AUTOSAR XML (schema 4-2-1)
package /RootP_ASWC_M418
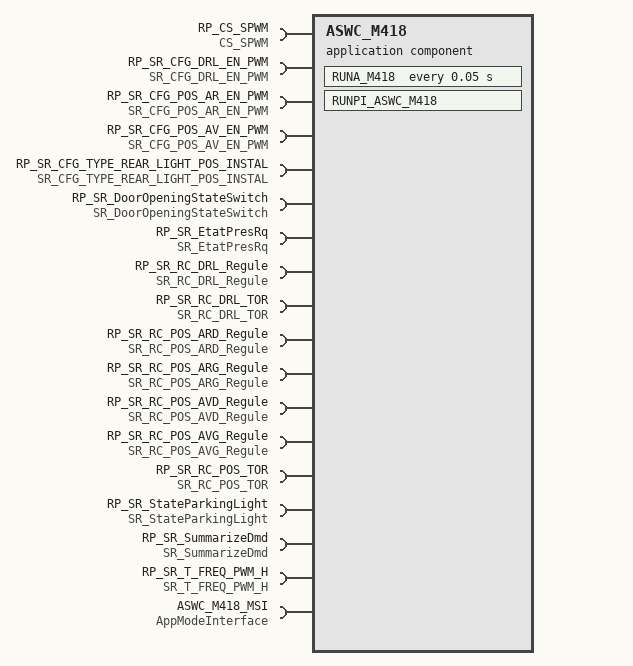
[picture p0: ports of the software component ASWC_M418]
  application sw component type ASWC_M418
    16 x provide/require port:
      PRP_SR_CmdDRL: nonqueued-receiver-com-spec{data-element=CmdDRL, enable-update=0, handle-data-status=1, handle-never-received=0, init-value=CONST_tLOG_0:0}, provided-required-interface=SR_CmdDRL
      PRP_SR_CmdFenderFxLPos: nonqueued-receiver-com-spec{data-element=CmdFenderFxLPos, enable-update=0, handle-data-status=1, handle-never-received=0, init-value=CONST_tLOG_0:0}, provided-required-interface=SR_CmdFenderFxLPos
      PRP_SR_CmdFenderFxRPos: nonqueued-receiver-com-spec{data-element=CmdFenderFxRPos, enable-update=0, handle-data-status=1, handle-never-received=0, init-value=CONST_tLOG_0:0}, provided-required-interface=SR_CmdFenderFxRPos
      PRP_SR_CmdFrontLPos: nonqueued-receiver-com-spec{data-element=CmdFrontLPos, enable-update=0, handle-data-status=1, handle-never-received=0, init-value=CONST_tLOG_0:0}, provided-required-interface=SR_CmdFrontLPos
      PRP_SR_CmdFrontRPos: nonqueued-receiver-com-spec{data-element=CmdFrontRPos, enable-update=0, handle-data-status=1, handle-never-received=0, init-value=CONST_tLOG_0:0}, provided-required-interface=SR_CmdFrontRPos
      PRP_SR_CmdLicensePlate: nonqueued-receiver-com-spec{data-element=CmdLicensePlate, enable-update=0, handle-data-status=1, handle-never-received=0, init-value=CONST_tLOG_0:0}, provided-required-interface=SR_CmdLicensePlate
      PRP_SR_CmdSideMarkersLeft: nonqueued-receiver-com-spec{data-element=CmdSideMarkersLeft, enable-update=0, handle-data-status=1, handle-never-received=0, init-value=CONST_tLOG_0:0}, provided-required-interface=SR_CmdSideMarkersLeft
      PRP_SR_CmdSideMarkersRight: nonqueued-receiver-com-spec{data-element=CmdSideMarkersRight, enable-update=0, handle-data-status=1, handle-never-received=0, init-value=CONST_tLOG_0:0}, provided-required-interface=SR_CmdSideMarkersRight
      PRP_SR_CmdSubstituteFxLPos: nonqueued-receiver-com-spec{data-element=CmdSubstituteFxLPos, enable-update=0, handle-data-status=1, handle-never-received=0, init-value=CONST_tLOG_0:0}, provided-required-interface=SR_CmdSubstituteFxLPos
      PRP_SR_CmdSubstituteFxRPos: nonqueued-receiver-com-spec{data-element=CmdSubstituteFxRPos, enable-update=0, handle-data-status=1, handle-never-received=0, init-value=CONST_tLOG_0:0}, provided-required-interface=SR_CmdSubstituteFxRPos
      PRP_SR_CmdTrailerFxPos: nonqueued-receiver-com-spec{data-element=CmdTrailerFxPos, enable-update=0, handle-data-status=1, handle-never-received=0, init-value=CONST_t_TrailerPositionLight_0:0}, provided-required-interface=SR_CmdTrailerFxPos
      PRP_SR_CmdTrunkFxLPos: nonqueued-receiver-com-spec{data-element=CmdTrunkFxLPos, enable-update=0, handle-data-status=1, handle-never-received=0, init-value=CONST_tLOG_0:0}, provided-required-interface=SR_CmdTrunkFxLPos
      PRP_SR_CmdTrunkFxRPos: nonqueued-receiver-com-spec{data-element=CmdTrunkFxRPos, enable-update=0, handle-data-status=1, handle-never-received=0, init-value=CONST_tLOG_0:0}, provided-required-interface=SR_CmdTrunkFxRPos
      PRP_SR_EtatFxDiurnes: nonqueued-receiver-com-spec{data-element=EtatFxDiurnes, enable-update=0, handle-data-status=1, handle-never-received=0, init-value=CONST_tLOG_0:0}, provided-required-interface=SR_EtatFxDiurnes
      PRP_SR_EtatFxPosition: nonqueued-receiver-com-spec{data-element=EtatFxPosition, enable-update=0, handle-data-status=1, handle-never-received=0, init-value=CONST_tLOG_0:0}, provided-required-interface=SR_EtatFxPosition
      PRP_SR_PositionLight: nonqueued-receiver-com-spec{data-element=PositionLight, enable-update=0, handle-data-status=1, handle-never-received=0, init-value=CONST_tLOG_0:0}, provided-required-interface=SR_PositionLight
    18 x require port:
      RP_CS_SPWM: required-interface=CS_SPWM
      RP_SR_CFG_DRL_EN_PWM: nonqueued-receiver-com-spec{data-element=CFG_DRL_EN_PWM, enable-update=0, handle-data-status=1, handle-never-received=0, init-value=CONST_tBYTE_1:1}, required-interface=SR_CFG_DRL_EN_PWM
      RP_SR_CFG_POS_AR_EN_PWM: nonqueued-receiver-com-spec{data-element=CFG_POS_AR_EN_PWM, enable-update=0, handle-data-status=1, handle-never-received=0, init-value=CONST_tBYTE_1:1}, required-interface=SR_CFG_POS_AR_EN_PWM
      RP_SR_CFG_POS_AV_EN_PWM: nonqueued-receiver-com-spec{data-element=CFG_POS_AV_EN_PWM, enable-update=0, handle-data-status=1, handle-never-received=0, init-value=CONST_tBYTE_1:1}, required-interface=SR_CFG_POS_AV_EN_PWM
      RP_SR_CFG_TYPE_REAR_LIGHT_POS_INSTAL: nonqueued-receiver-com-spec{data-element=CFG_TYPE_REAR_LIGHT_POS_INSTAL, enable-update=0, handle-data-status=1, handle-never-received=0, init-value=CONST_t_TypeRearLightInstall_0:0}, required-interface=SR_CFG_TYPE_REAR_LIGHT_POS_INSTAL
      RP_SR_DoorOpeningStateSwitch: nonqueued-receiver-com-spec{data-element=DoorOpeningState, enable-update=0, handle-data-status=1, handle-never-received=0, init-value=CONST_DoorOpeningState_tOpeningPosition_eMVA_None:0}, required-interface=SR_DoorOpeningStateSwitch
      RP_SR_EtatPresRq: nonqueued-receiver-com-spec{data-element=EtatPresRq, enable-update=0, handle-data-status=1, handle-never-received=0, init-value=CONST_tLOG_0:0}, required-interface=SR_EtatPresRq
      RP_SR_RC_DRL_Regule: nonqueued-receiver-com-spec{data-element=RC_DRL_Regule, enable-update=0, handle-data-status=1, handle-never-received=0, init-value=CONST_tWORD_100:100}, required-interface=SR_RC_DRL_Regule
      RP_SR_RC_DRL_TOR: nonqueued-receiver-com-spec{data-element=RC_DRL_TOR, enable-update=0, handle-data-status=1, handle-never-received=0, init-value=CONST_tWORD_255:255}, required-interface=SR_RC_DRL_TOR
      RP_SR_RC_POS_ARD_Regule: nonqueued-receiver-com-spec{data-element=RC_POS_ARD_Regule, enable-update=0, handle-data-status=1, handle-never-received=0, init-value=CONST_tWORD_100:100}, required-interface=SR_RC_POS_ARD_Regule
      RP_SR_RC_POS_ARG_Regule: nonqueued-receiver-com-spec{data-element=RC_POS_ARG_Regule, enable-update=0, handle-data-status=1, handle-never-received=0, init-value=CONST_tWORD_100:100}, required-interface=SR_RC_POS_ARG_Regule
      RP_SR_RC_POS_AVD_Regule: nonqueued-receiver-com-spec{data-element=RC_POS_AVD_Regule, enable-update=0, handle-data-status=1, handle-never-received=0, init-value=CONST_tWORD_100:100}, required-interface=SR_RC_POS_AVD_Regule
      RP_SR_RC_POS_AVG_Regule: nonqueued-receiver-com-spec{data-element=RC_POS_AVG_Regule, enable-update=0, handle-data-status=1, handle-never-received=0, init-value=CONST_tWORD_100:100}, required-interface=SR_RC_POS_AVG_Regule
      RP_SR_RC_POS_TOR: nonqueued-receiver-com-spec{data-element=RC_POS_TOR, enable-update=0, handle-data-status=1, handle-never-received=0, init-value=CONST_tWORD_255:255}, required-interface=SR_RC_POS_TOR
      RP_SR_StateParkingLight: nonqueued-receiver-com-spec{data-element=StateParkingLight, enable-update=0, handle-data-status=1, handle-never-received=0, init-value=CONST_t_StateParkingLight_0:0}, required-interface=SR_StateParkingLight
      RP_SR_SummarizeDmd: required-interface=SR_SummarizeDmd
        required-com-specs:
          data-element=SummarizeDmd_DRL, enable-update=0, handle-data-status=1, handle-never-received=0, init-value=CONST_tLOG_0:0
          data-element=SummarizeDmd_Position, enable-update=0, handle-data-status=1, handle-never-received=0, init-value=CONST_tLOG_0:0
      RP_SR_T_FREQ_PWM_H: nonqueued-receiver-com-spec{data-element=T_FREQ_PWM_H, enable-update=0, handle-data-status=1, handle-never-received=0, init-value=CONST_tWORD_7:7}, required-interface=SR_T_FREQ_PWM_H
      ASWC_M418_MSI: required-interface=AppModeInterface
    behavior IB_ASWC_M418: data-type-mapping=ApplicationModeMapping, handle-termination-and-restart=NO-SUPPORT
      ar-typed-per-instance-memorys:
        5 x data, all with type=tLOG, init-value=CONST_tLOG_0:0:
          PIM_M418_CmdDRL_Prec
          PIM_M418_CmdFenderL_Prec
          PIM_M418_CmdFenderR_Prec
          PIM_M418_CmdFrontL_Prec
          PIM_M418_CmdFrontR_Prec
      timing event RUNA_M418_Cyclic: start-on-event=RUNA_M418, period=0.05
        disabled-mode:
          ASWC_M418_MSI.AppMode.APP_WAKEUP
          ASWC_M418_MSI.AppMode.APP_OFF
          ASWC_M418_MSI.AppMode.APP_SYNC_INIT
          ASWC_M418_MSI.AppMode.APP_CONFIG
      swc mode switch event RUNPI_ASWC_M418_ENTRY: start-on-event=RUNPI_ASWC_M418, activation=ON-ENTRY, mode=ASWC_M418_MSI.AppMode.APP_WAKEUP
      runnable RUNA_M418
        data-read-access:
          33 x access:
            dra_RP_SR_DoorOpeningStateSwitch_DoorOpeningState: accessed-variable=RP_SR_DoorOpeningStateSwitch.DoorOpeningState
            dra_RP_SR_EtatPresRq_EtatPresRq: accessed-variable=RP_SR_EtatPresRq.EtatPresRq
            dra_RP_SR_StateParkingLight_StateParkingLight: accessed-variable=RP_SR_StateParkingLight.StateParkingLight
            dra_RP_SR_SummarizeDmd_SummarizeDmd_DRL: accessed-variable=RP_SR_SummarizeDmd.SummarizeDmd_DRL
            dra_RP_SR_SummarizeDmd_SummarizeDmd_Position: accessed-variable=RP_SR_SummarizeDmd.SummarizeDmd_Position
            dra_RP_SR_CFG_DRL_EN_PWM_CFG_DRL_EN_PWM: accessed-variable=RP_SR_CFG_DRL_EN_PWM.CFG_DRL_EN_PWM
            dra_RP_SR_CFG_POS_AR_EN_PWM_CFG_POS_AR_EN_PWM: accessed-variable=RP_SR_CFG_POS_AR_EN_PWM.CFG_POS_AR_EN_PWM
            dra_RP_SR_CFG_POS_AV_EN_PWM_CFG_POS_AV_EN_PWM: accessed-variable=RP_SR_CFG_POS_AV_EN_PWM.CFG_POS_AV_EN_PWM
            dra_RP_SR_CFG_TYPE_REAR_LIGHT_POS_INSTAL_CFG_TYPE_REAR_LIGHT_POS_INSTAL: accessed-variable=RP_SR_CFG_TYPE_REAR_LIGHT_POS_INSTAL.CFG_TYPE_REAR_LIGHT_POS_INSTAL
            dra_RP_SR_RC_DRL_Regule_RC_DRL_Regule: accessed-variable=RP_SR_RC_DRL_Regule.RC_DRL_Regule
            dra_RP_SR_RC_DRL_TOR_RC_DRL_TOR: accessed-variable=RP_SR_RC_DRL_TOR.RC_DRL_TOR
            dra_RP_SR_RC_POS_ARD_Regule_RC_POS_ARD_Regule: accessed-variable=RP_SR_RC_POS_ARD_Regule.RC_POS_ARD_Regule
            dra_RP_SR_RC_POS_ARG_Regule_RC_POS_ARG_Regule: accessed-variable=RP_SR_RC_POS_ARG_Regule.RC_POS_ARG_Regule
            dra_RP_SR_RC_POS_AVD_Regule_RC_POS_AVD_Regule: accessed-variable=RP_SR_RC_POS_AVD_Regule.RC_POS_AVD_Regule
            dra_RP_SR_RC_POS_AVG_Regule_RC_POS_AVG_Regule: accessed-variable=RP_SR_RC_POS_AVG_Regule.RC_POS_AVG_Regule
            dra_RP_SR_RC_POS_TOR_RC_POS_TOR: accessed-variable=RP_SR_RC_POS_TOR.RC_POS_TOR
            dra_RP_SR_T_FREQ_PWM_H_T_FREQ_PWM_H: accessed-variable=RP_SR_T_FREQ_PWM_H.T_FREQ_PWM_H
            dra_PRP_SR_CmdDRL_CmdDRL: accessed-variable=PRP_SR_CmdDRL.CmdDRL
            dra_PRP_SR_CmdFenderFxLPos_CmdFenderFxLPos: accessed-variable=PRP_SR_CmdFenderFxLPos.CmdFenderFxLPos
            dra_PRP_SR_CmdFenderFxRPos_CmdFenderFxRPos: accessed-variable=PRP_SR_CmdFenderFxRPos.CmdFenderFxRPos
            dra_PRP_SR_CmdFrontLPos_CmdFrontLPos: accessed-variable=PRP_SR_CmdFrontLPos.CmdFrontLPos
            dra_PRP_SR_CmdFrontRPos_CmdFrontRPos: accessed-variable=PRP_SR_CmdFrontRPos.CmdFrontRPos
            dra_PRP_SR_CmdLicensePlate_CmdLicensePlate: accessed-variable=PRP_SR_CmdLicensePlate.CmdLicensePlate
            dra_PRP_SR_CmdSideMarkersLeft_CmdSideMarkersLeft: accessed-variable=PRP_SR_CmdSideMarkersLeft.CmdSideMarkersLeft
            dra_PRP_SR_CmdSideMarkersRight_CmdSideMarkersRight: accessed-variable=PRP_SR_CmdSideMarkersRight.CmdSideMarkersRight
            dra_PRP_SR_CmdSubstituteFxLPos_CmdSubstituteFxLPos: accessed-variable=PRP_SR_CmdSubstituteFxLPos.CmdSubstituteFxLPos
            dra_PRP_SR_CmdSubstituteFxRPos_CmdSubstituteFxRPos: accessed-variable=PRP_SR_CmdSubstituteFxRPos.CmdSubstituteFxRPos
            dra_PRP_SR_CmdTrailerFxPos_CmdTrailerFxPos: accessed-variable=PRP_SR_CmdTrailerFxPos.CmdTrailerFxPos
            dra_PRP_SR_CmdTrunkFxLPos_CmdTrunkFxLPos: accessed-variable=PRP_SR_CmdTrunkFxLPos.CmdTrunkFxLPos
            dra_PRP_SR_CmdTrunkFxRPos_CmdTrunkFxRPos: accessed-variable=PRP_SR_CmdTrunkFxRPos.CmdTrunkFxRPos
            dra_PRP_SR_EtatFxDiurnes_EtatFxDiurnes: accessed-variable=PRP_SR_EtatFxDiurnes.EtatFxDiurnes
            dra_PRP_SR_EtatFxPosition_EtatFxPosition: accessed-variable=PRP_SR_EtatFxPosition.EtatFxPosition
            dra_PRP_SR_PositionLight_PositionLight: accessed-variable=PRP_SR_PositionLight.PositionLight
        data-write-access:
          16 x access:
            dwa_PRP_SR_CmdDRL_CmdDRL: accessed-variable=PRP_SR_CmdDRL.CmdDRL
            dwa_PRP_SR_CmdFenderFxLPos_CmdFenderFxLPos: accessed-variable=PRP_SR_CmdFenderFxLPos.CmdFenderFxLPos
            dwa_PRP_SR_CmdFenderFxRPos_CmdFenderFxRPos: accessed-variable=PRP_SR_CmdFenderFxRPos.CmdFenderFxRPos
            dwa_PRP_SR_CmdFrontLPos_CmdFrontLPos: accessed-variable=PRP_SR_CmdFrontLPos.CmdFrontLPos
            dwa_PRP_SR_CmdFrontRPos_CmdFrontRPos: accessed-variable=PRP_SR_CmdFrontRPos.CmdFrontRPos
            dwa_PRP_SR_CmdLicensePlate_CmdLicensePlate: accessed-variable=PRP_SR_CmdLicensePlate.CmdLicensePlate
            dwa_PRP_SR_CmdSideMarkersLeft_CmdSideMarkersLeft: accessed-variable=PRP_SR_CmdSideMarkersLeft.CmdSideMarkersLeft
            dwa_PRP_SR_CmdSideMarkersRight_CmdSideMarkersRight: accessed-variable=PRP_SR_CmdSideMarkersRight.CmdSideMarkersRight
            dwa_PRP_SR_CmdSubstituteFxLPos_CmdSubstituteFxLPos: accessed-variable=PRP_SR_CmdSubstituteFxLPos.CmdSubstituteFxLPos
            dwa_PRP_SR_CmdSubstituteFxRPos_CmdSubstituteFxRPos: accessed-variable=PRP_SR_CmdSubstituteFxRPos.CmdSubstituteFxRPos
            dwa_PRP_SR_CmdTrailerFxPos_CmdTrailerFxPos: accessed-variable=PRP_SR_CmdTrailerFxPos.CmdTrailerFxPos
            dwa_PRP_SR_CmdTrunkFxLPos_CmdTrunkFxLPos: accessed-variable=PRP_SR_CmdTrunkFxLPos.CmdTrunkFxLPos
            dwa_PRP_SR_CmdTrunkFxRPos_CmdTrunkFxRPos: accessed-variable=PRP_SR_CmdTrunkFxRPos.CmdTrunkFxRPos
            dwa_PRP_SR_EtatFxDiurnes_EtatFxDiurnes: accessed-variable=PRP_SR_EtatFxDiurnes.EtatFxDiurnes
            dwa_PRP_SR_EtatFxPosition_EtatFxPosition: accessed-variable=PRP_SR_EtatFxPosition.EtatFxPosition
            dwa_PRP_SR_PositionLight_PositionLight: accessed-variable=PRP_SR_PositionLight.PositionLight
        sync call sscp_RUNA_M418_CS_SPWM_Set: operation=RP_CS_SPWM.Set, timeout=0
      runnable RUNPI_ASWC_M418
package /RootP_Implementatation
  swc implementation Implementatation_ASWC_M418: programming-language=C, sw-version=1.0.0, vendor-id=1, behavior=IB_ASWC_M418
    code-descriptors:
      code SRC: artifact-descriptors=autosar-engineering-object={short-label=EngObject, category=SWSRC}
    resource consumption Resources
